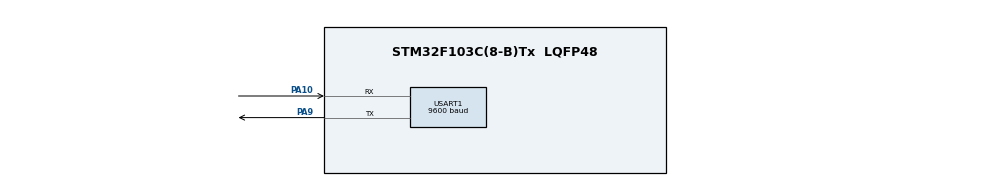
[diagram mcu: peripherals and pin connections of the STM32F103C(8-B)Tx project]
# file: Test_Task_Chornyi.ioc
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Mcu.Family=STM32F1
Mcu.Name=STM32F103C(8-B)Tx
Mcu.Package=LQFP48
NVIC.PriorityGroup=NVIC_PRIORITYGROUP_4
NVIC.USART1_IRQn=true\:0\:0\:false\:false\:true\:true\:true\:true
PA10.Mode=Asynchronous
PA10.Signal=USART1_RX
PA9.Mode=Asynchronous
PA9.Signal=USART1_TX
ProjectManager.HeapSize=0x200
ProjectManager.StackSize=0x400
ProjectManager.TargetToolchain=STM32CubeIDE
RCC.APB1Freq_Value=8000000
RCC.APB2Freq_Value=8000000
USART1.BaudRate=9600
USART1.VirtualMode=VM_ASYNC
VP_SYS_VS_ND.Mode=No_Debug
board=custom

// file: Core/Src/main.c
/* USER CODE BEGIN Header */
/**
  ******************************************************************************
  * @file           : main.c
  * @brief          : Main program body
  ******************************************************************************
  * @attention
  *
  * Copyright (c) 2024 STMicroelectronics.
  * All rights reserved.
  *
  * This software is licensed under terms that can be found in the LICENSE file
  * in the root directory of this software component.
  * If no LICENSE file comes with this software, it is provided AS-IS.
  *
  ******************************************************************************
  */
/* USER CODE END Header */
#include "main.h"
#include <string.h>
#include <stdio.h>
#include <stdlib.h>
#include <ctype.h>

/* USER CODE BEGIN PTD */
typedef struct {
    int16_t x;
    int16_t y;
} Point;
/* USER CODE END PTD */

/* USER CODE BEGIN PD */
#define ARRAY_SIZE(array) (sizeof(array) / sizeof(array[0]))
/* USER CODE END PD */

UART_HandleTypeDef huart1;

/* USER CODE BEGIN PV */
static char tx_buffer[32] = {0};
static char buffer[32] = {0};
static uint8_t indx = 0;

static uint8_t rx_buffer[1];

const Point points[] = {
    {0, 1},
    {10, 20},
    {20, 30},
    {30, 25},
    {40, 35},
    {50, 50}
};

/* USER CODE END PV */

void SystemClock_Config(void);
static void MX_GPIO_Init(void);
static void MX_USART1_UART_Init(void);

/* USER CODE BEGIN 0 */
int16_t lagrange_interpolation(int16_t x) {
    double result = 0;
    for (int i = 0; i < ARRAY_SIZE(points); i++) {
        double term = points[i].y;
        for (int j = 0; j < ARRAY_SIZE(points); j++) {
            if (i != j) {
                term *= (double)(x - points[j].x) / (points[i].x - points[j].x);
            }
        }
        result += term;
    }
    return result;
}

void HAL_UART_RxCpltCallback(UART_HandleTypeDef *huart) {
	// Check that the interruption is caused by UART1
	if(huart->Instance == USART1) {
		// Flag to check if a digit is found in the input data from UART1
		static uint8_t is_founded_number = 0;

		// Inserting data from the input buffer into the string buffer
		memcpy(buffer + indx, rx_buffer, ARRAY_SIZE(rx_buffer));

		// Check to ensure that the buffer is not exceeded
		if(++indx == ARRAY_SIZE(buffer) - 1) {
			indx = 0;
			is_founded_number = 0;
		}

		// Checking that there is a number among the input data
		if(isdigit(rx_buffer[0])) {
		    is_founded_number = 1;
		}

		// Searching for CRLT in the buffer
		if(strstr(buffer, "\r\n") != 0) {
			if(is_founded_number) {
				// Resetting the buffer backlog
				memset(buffer + indx, 0, sizeof(buffer) - indx);

				// Copying string buffer to tx_buffer, in order to secure the future transmission of the response on the UART from new input data
				memcpy(tx_buffer, buffer, sizeof(buffer));

				// Finding y through the Lagrange polynomial
				int16_t y = lagrange_interpolation(atoi(tx_buffer));

				// Writing to tx_buffer the response with CRLT
				snprintf(tx_buffer, sizeof(tx_buffer), "%d\r\n", y);

				// Sending via UART1
				HAL_UART_Transmit(&huart1, tx_buffer, strlen(tx_buffer), 50);

				is_founded_number = 0;
			}
			indx = 0;
		}
		// Cyclic gartering of UART1 for Callback operation continuously
		HAL_UART_Receive_IT(&huart1, rx_buffer, ARRAY_SIZE(rx_buffer));
	}
}

/* USER CODE END 0 */

int main(void)
{

  /* MCU Configuration--------------------------------------------------------*/

  /* Reset of all peripherals, Initializes the Flash interface and the Systick. */
  HAL_Init();

  /* Configure the system clock */
  SystemClock_Config();

  /* Initialize all configured peripherals */
  MX_GPIO_Init();
  MX_USART1_UART_Init();
  /* USER CODE BEGIN 2 */

  // HAL_UART_Receive_IT calls HAL_UART_RxCpltCallback after receiving each character on the UART
  HAL_UART_Receive_IT(&huart1, rx_buffer, ARRAY_SIZE(rx_buffer));

  /* USER CODE END 2 */

  /* Infinite loop */
  while (1)
  {
	  HAL_Delay(10);
  }
}

void SystemClock_Config(void)
{
  RCC_OscInitTypeDef RCC_OscInitStruct = {0};
  RCC_ClkInitTypeDef RCC_ClkInitStruct = {0};

  /** Initializes the RCC Oscillators according to the specified parameters
  * in the RCC_OscInitTypeDef structure.
  */
  RCC_OscInitStruct.OscillatorType = RCC_OSCILLATORTYPE_HSI;
  RCC_OscInitStruct.HSIState = RCC_HSI_ON;
  RCC_OscInitStruct.HSICalibrationValue = RCC_HSICALIBRATION_DEFAULT;
  RCC_OscInitStruct.PLL.PLLState = RCC_PLL_NONE;
  if (HAL_RCC_OscConfig(&RCC_OscInitStruct) != HAL_OK)
  {
    Error_Handler();
  }

  /** Initializes the CPU, AHB and APB buses clocks
  */
  RCC_ClkInitStruct.ClockType = RCC_CLOCKTYPE_HCLK|RCC_CLOCKTYPE_SYSCLK
                              |RCC_CLOCKTYPE_PCLK1|RCC_CLOCKTYPE_PCLK2;
  RCC_ClkInitStruct.SYSCLKSource = RCC_SYSCLKSOURCE_HSI;
  RCC_ClkInitStruct.AHBCLKDivider = RCC_SYSCLK_DIV1;
  RCC_ClkInitStruct.APB1CLKDivider = RCC_HCLK_DIV1;
  RCC_ClkInitStruct.APB2CLKDivider = RCC_HCLK_DIV1;

  if (HAL_RCC_ClockConfig(&RCC_ClkInitStruct, FLASH_LATENCY_0) != HAL_OK)
  {
    Error_Handler();
  }
}

static void MX_USART1_UART_Init(void)
{

  huart1.Instance = USART1;
  huart1.Init.BaudRate = 9600;
  huart1.Init.WordLength = UART_WORDLENGTH_8B;
  huart1.Init.StopBits = UART_STOPBITS_1;
  huart1.Init.Parity = UART_PARITY_NONE;
  huart1.Init.Mode = UART_MODE_TX_RX;
  huart1.Init.HwFlowCtl = UART_HWCONTROL_NONE;
  huart1.Init.OverSampling = UART_OVERSAMPLING_16;
  if (HAL_UART_Init(&huart1) != HAL_OK)
  {
    Error_Handler();
  }

}

static void MX_GPIO_Init(void)
{

  /* GPIO Ports Clock Enable */
  __HAL_RCC_GPIOA_CLK_ENABLE();

}

void Error_Handler(void)
{
  __disable_irq();
  while (1)
  {
  }
}
